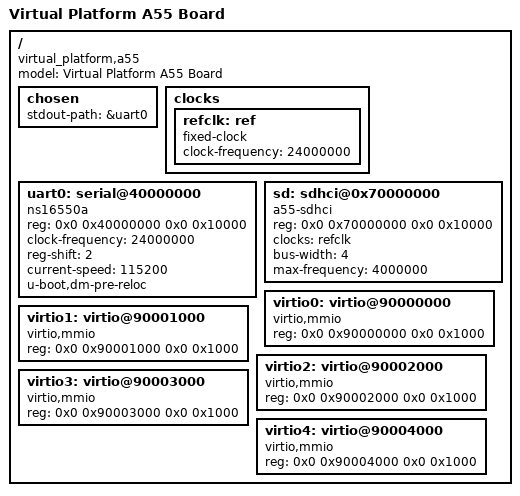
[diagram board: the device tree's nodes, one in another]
// SPDX-License-Identifier: BSD-2-Clause
/*
 * Copyright (C) 2023 Thomas coding.
 */

/dts-v1/;

#include <configs/a55.h>


/ {
	compatible = "virtual_platform,a55";
	model = "Virtual Platform A55 Board";

	#address-cells = <2>;
	#size-cells = <2>;

	chosen {
		stdout-path = &uart0;
	};

	clocks {
		refclk: ref {
			compatible = "fixed-clock";
			#clock-cells = <0>;
			clock-frequency = <24000000>;
		};
	};

	uart0: serial@40000000 {
		compatible = "ns16550a";
		reg = <0x0 0x40000000 0x0 0x10000>;
		clock-frequency = <24000000>;
		reg-shift = <2>;
		current-speed = <115200>;
		u-boot,dm-pre-reloc;
	};

	sd: sdhci@0x70000000 {
		compatible = "a55-sdhci";
		reg = <0x0 0x70000000 0x0 0x10000>;
		clocks = <&refclk>;
		bus-width = <4>;
		max-frequency = <4000000>;
	};

	virtio0: virtio@90000000 {
		compatible = "virtio,mmio";
		reg = <0x0 0x90000000 0x0 0x1000>;
	};

	virtio1: virtio@90001000 {
		compatible = "virtio,mmio";
		reg = <0x0 0x90001000 0x0 0x1000>;
	};

	virtio2: virtio@90002000 {
		compatible = "virtio,mmio";
		reg = <0x0 0x90002000 0x0 0x1000>;
	};

	virtio3: virtio@90003000 {
		compatible = "virtio,mmio";
		reg = <0x0 0x90003000 0x0 0x1000>;
	};

	virtio4: virtio@90004000 {
		compatible = "virtio,mmio";
		reg = <0x0 0x90004000 0x0 0x1000>;
	};
};
